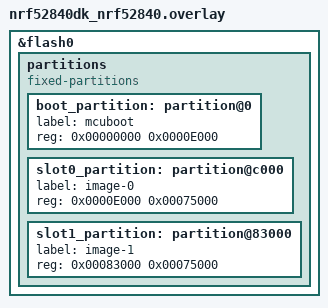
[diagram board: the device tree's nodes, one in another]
/* Copyright (c) 2019 Nordic Semiconductor ASA
 *
 * SPDX-License-Identifier: Apache-2.0
 */

/delete-node/ &boot_partition;
/delete-node/ &slot0_partition;
/delete-node/ &slot1_partition;

&flash0 {

	partitions {
		compatible = "fixed-partitions";
		#address-cells = <1>;
		#size-cells = <1>;

		boot_partition: partition@0 {
			label = "mcuboot";
			reg = <0x00000000 0x0000E000>;
		};
		slot0_partition: partition@c000 {
			label = "image-0";
			reg = <0x0000E000 0x00075000>;
		};
		slot1_partition: partition@83000 {
			label = "image-1";
			reg = <0x00083000 0x00075000>;
		};
	};
};
